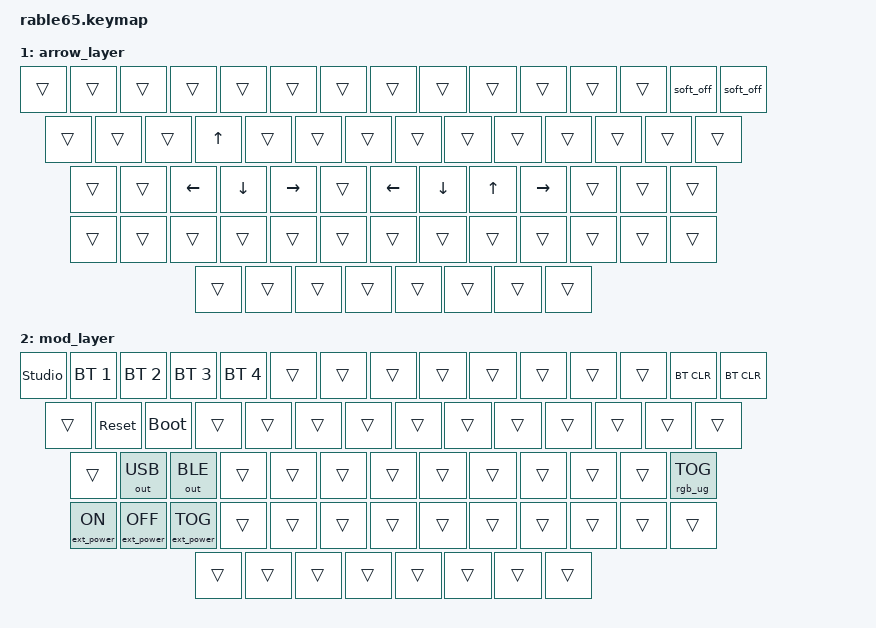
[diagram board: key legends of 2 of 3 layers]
/*
 * Copyright (c) 2021 Nick Winans
 *
 * SPDX-License-Identifier: MIT
 */

#include <behaviors.dtsi>
#include <dt-bindings/zmk/keys.h>
#include <dt-bindings/zmk/rgb.h>
#include <dt-bindings/zmk/bt.h>
#include <dt-bindings/zmk/outputs.h>
#include <dt-bindings/zmk/ext_power.h>

&soft_off {
    hold-time-ms = <2000>;
};

/ {
  keymap {
    compatible = "zmk,keymap";
    
    default_layer {
      bindings = <
        &gresc     &kp N1   &kp N2   &kp N3   &kp N4   &kp N5   &kp N6   &kp N7   &kp N8     &kp N9   &kp N0    &kp MINUS  &kp EQUAL  &kp BSPC  &kp BSPC &kp HOME
        &kp TAB    &kp Q    &kp W    &kp E    &kp R    &kp T    &kp Y    &kp U    &kp I      &kp O    &kp P     &kp LBKT   &kp RBKT       &kp BSLH  &kp PGUP
        &kp CLCK   &kp A    &kp S  &kp D    &kp F    &kp G    &kp H    &kp J    &kp K      &kp L    &kp SEMI  &kp SQT           &kp RET     &kp PGDN              
        &kp LSHFT  &kp Z    &kp X    &kp C    &kp V    &kp B    &kp N    &kp M    &kp COMMA  &kp DOT  &kp FSLH            &kp RSHFT   &kp UP    &kp END
        &kp LCTRL  &kp LALT &kp LGUI                                  &kp SPACE                               &mo 1   &kp LCTRL  &kp LEFT &kp DOWN  &kp RIGHT
      >;
      sensor-bindings = <&inc_dec_kp C_VOLUME_DOWN C_VOLUME_UP>;
    };

    arrow_layer {
        // Hold Fn + either Backspace position for over 2 seconds, then release to power off.
        // ----------------------------------------------------------------------------------------------------------------
        // |        |    |     |     |     |     |     |     |     |     |     |     |     |     |     |   `~    |
        // |        |    |     |     |     |     |     |     |     |     |     |     |     |     |     |         |
        // |        |    |     |     |     |     |     |LEFT |DOWN |  UP |RIGHT|     |     |     |     |         |
        // |        |    |     |     |     |     |     |     |     |     |     |     |     |     |     |         |
        // |        |    |     |     |                                               |     |     |     |         |
        // ----------------------------------------------------------------------------------------------------------------
      bindings = <
        &trans    &trans   &trans    &trans   &trans    &trans   &trans    &trans   &trans    &trans   &trans    &trans   &trans    &soft_off   &soft_off
        &trans   &trans   &trans    &kp UP   &trans    &trans   &trans    &trans   &trans    &trans   &trans    &trans   &trans         &trans       
        &trans  &trans   &kp LEFT   &kp DOWN   &kp RIGHT  &trans   &kp LEFT  &kp DOWN &kp UP   &kp RIGHT &trans    &trans            &trans              
        &trans  &trans   &trans    &trans   &trans    &trans   &trans    &trans   &trans    &trans   &trans                       &trans   &trans    
        &trans   &trans   &trans                                   &trans                                        &trans      &trans    &trans   &trans   
      >;
    };
    
    mod_layer {
        // ----------------------------------------------------------------------------------------------------------------
        // |        |    | BT 1|BT 2 |BT 3 |BT 4 |     |     |     |     |     |     |     |     |BT CLR |         |
        // |        |    | RST | BOOT|     |     |     |     |     |     |     |     |     |     |       |         |
        // |        |    | USB | BLE |     |     |     |     |     |     |     |     |     |     |RGB TOG|         |
        // |        |    |EP_ON|EP_OFF|EP_TOG|     |     |     |     |     |     |     |     |     |       |         |
        // |        |    |     |     |                                               |     |     |       |         |
        // ----------------------------------------------------------------------------------------------------------------
      bindings = <
        &studio_unlock  &bt BT_SEL 1  &bt BT_SEL 2   &bt BT_SEL 3  &bt BT_SEL 4   &trans   &trans    &trans   &trans    &trans   &trans    &trans   &trans   &bt BT_CLR   &bt BT_CLR        
        &trans  &sys_reset     &bootloader   &trans    &trans    &trans   &trans   &trans   &trans   &trans   &trans   &trans   &trans   &trans   
        &trans  &out OUT_USB   &out OUT_BLE    &trans   &trans    &trans   &trans    &trans   &trans    &trans   &trans    &trans            &rgb_ug RGB_TOG           
        &ext_power EP_ON  &ext_power EP_OFF   &ext_power EP_TOG    &trans   &trans    &trans   &trans    &trans   &trans    &trans   &trans                       &trans   &trans        
        &trans   &trans   &trans                                   &trans                                         &trans   &trans     &trans   &trans  
      >;
    };
    
  };
};
